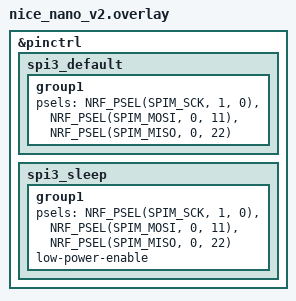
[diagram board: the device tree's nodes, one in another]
#include <dt-bindings/led/led.h>

&pinctrl {
    spi3_default: spi3_default {
        group1 {
            psels = <NRF_PSEL(SPIM_SCK, 1, 0)>,
                    <NRF_PSEL(SPIM_MOSI, 0, 11)>,
                    <NRF_PSEL(SPIM_MISO, 0, 22)>;
        };
    };

    spi3_sleep: spi3_sleep {
        group1 {
            psels = <NRF_PSEL(SPIM_SCK, 1, 0)>,
                    <NRF_PSEL(SPIM_MOSI, 0, 11)>,
                    <NRF_PSEL(SPIM_MISO, 0, 22)>;
            low-power-enable;
        };
    };
};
